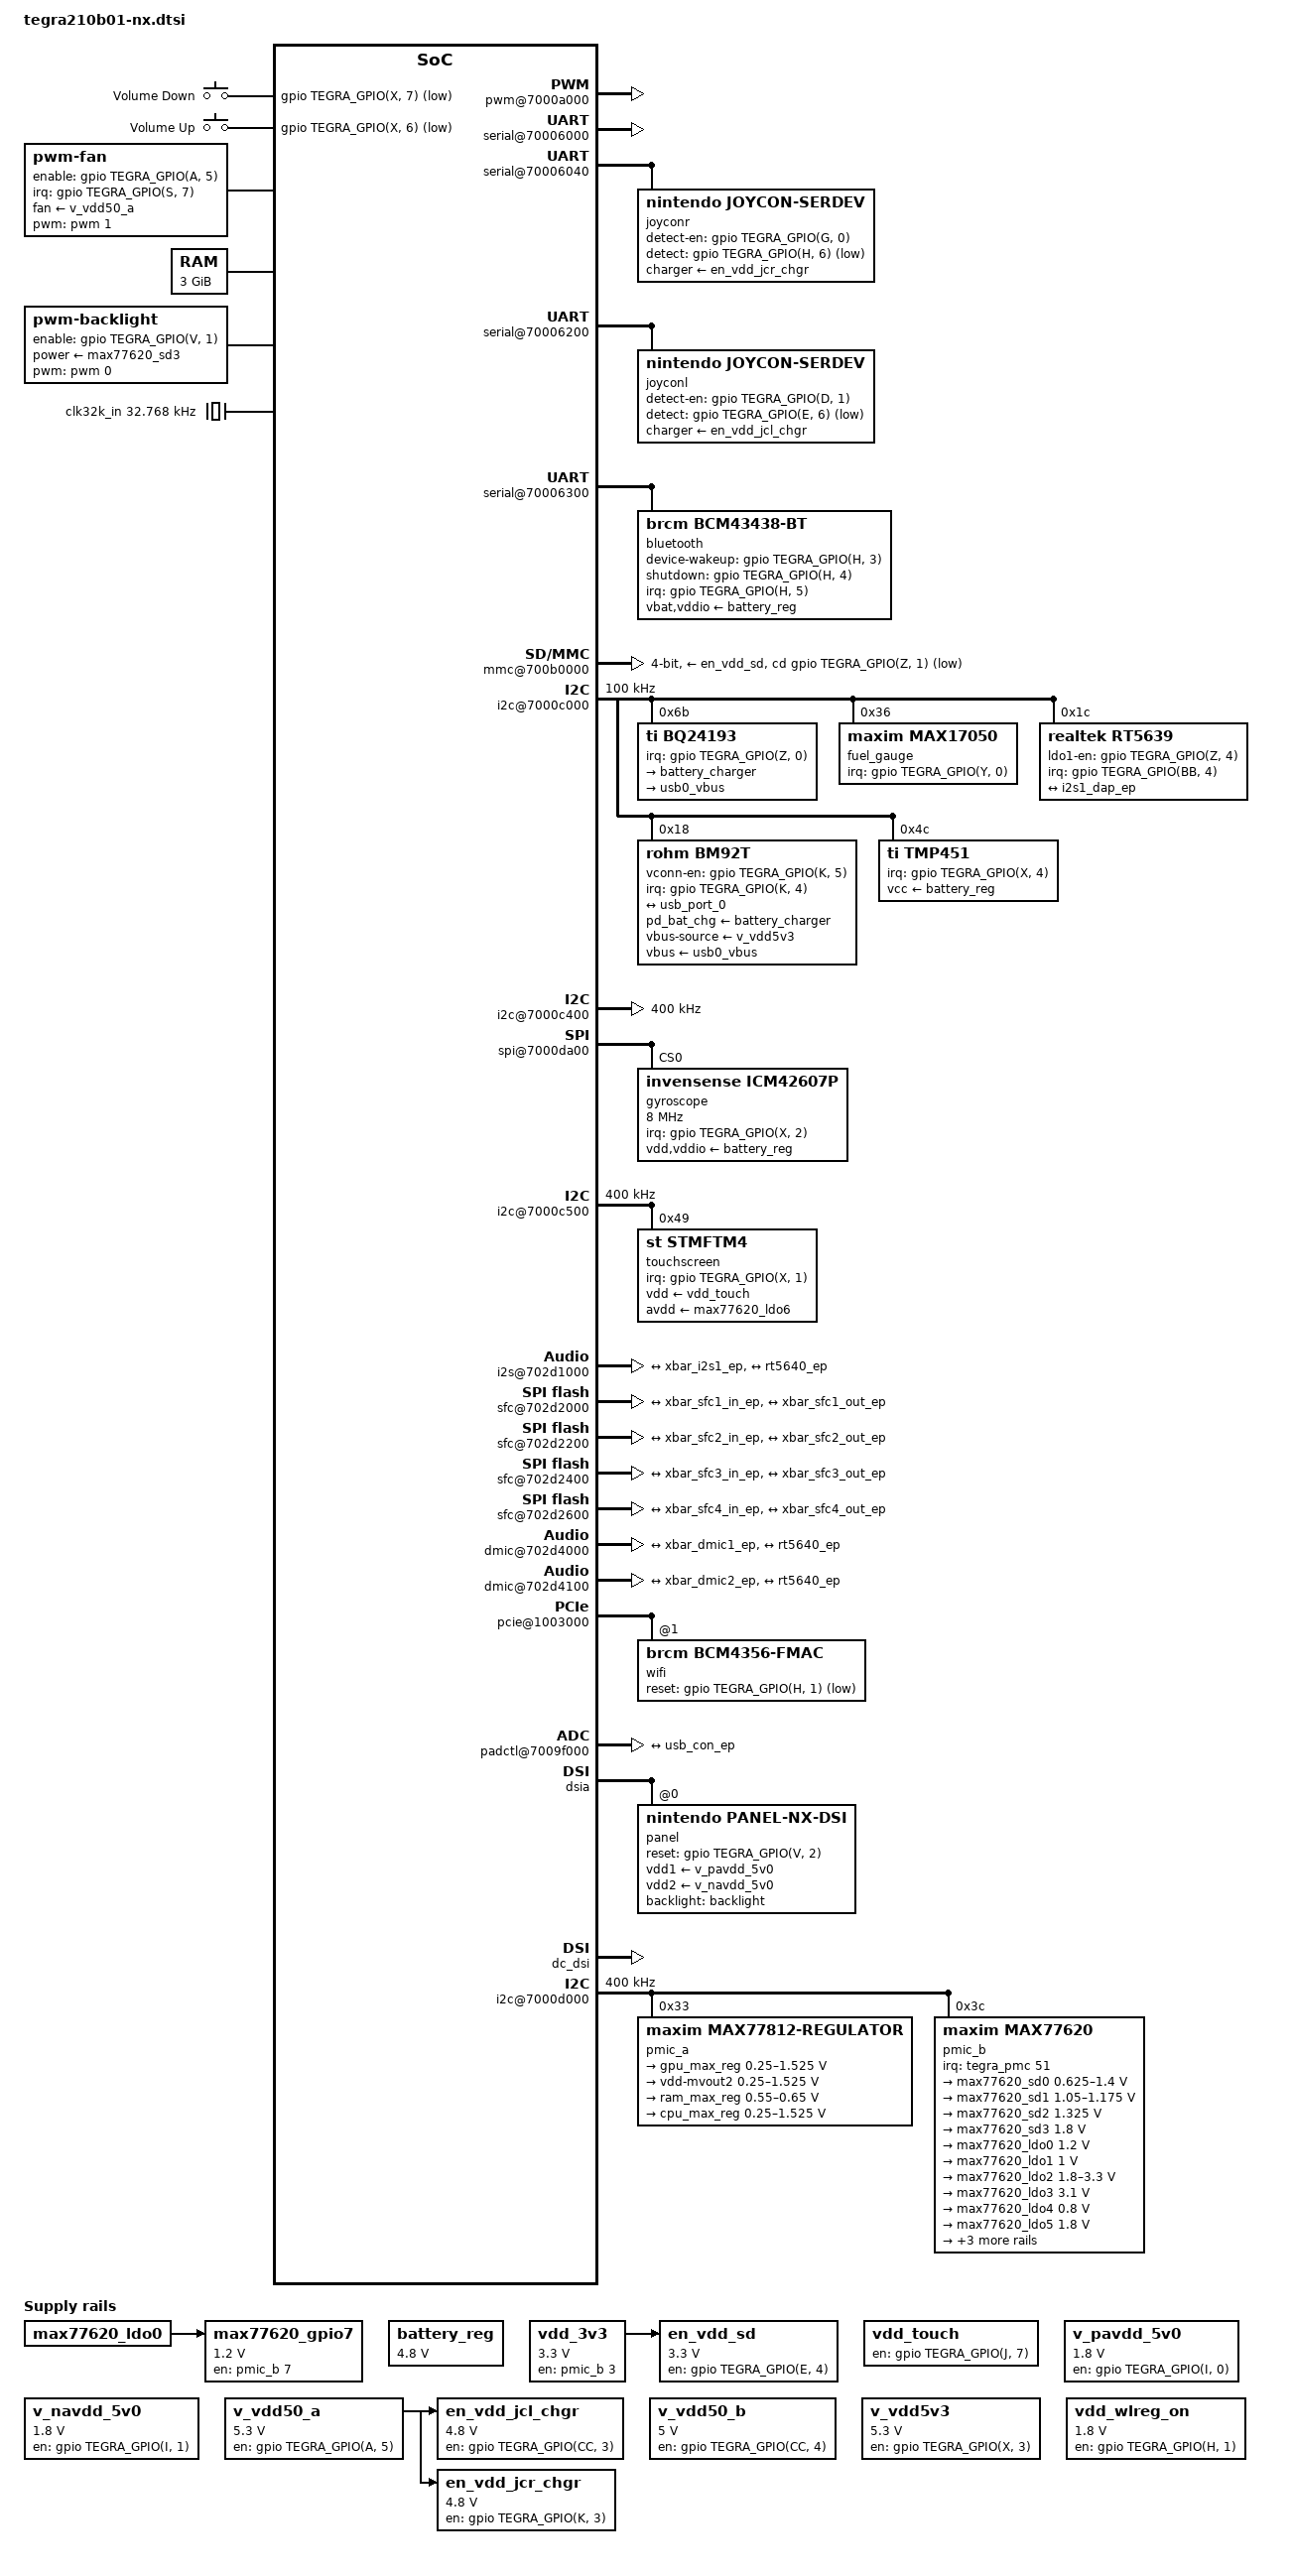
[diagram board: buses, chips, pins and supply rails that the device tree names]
// SPDX-License-Identifier: GPL-2.0
#include <dt-bindings/mfd/max77620.h>
#include <dt-bindings/thermal/thermal.h>
#include <dt-bindings/input/input.h>
#include <dt-bindings/pinctrl/pinctrl-tegra-io-pad.h>
#include <dt-bindings/soc/tegra-pmc.h>
#include <dt-bindings/sound/rt5640.h>

#include "tegra210b01.dtsi"

/ {
	aliases {
		serial0 = &uarta;
		serial1 = &uartb;
		serial2 = &uartc;
		serial3 = &uartd;
	};

	chosen {
		stdout-path = "serial0:115200n8";

		framebuffer {
			compatible = "simple-framebuffer";
			status = "disabled";
			memory-region = <&bootloader_fb>;
			width = <720>;
			height = <1280>;
			stride = <2880>;
			format = "a8b8g8r8";
			clocks = <&tegra_car TEGRA210_CLK_DISP1>,
				 <&tegra_car TEGRA210_CLK_DSIA>,
				 <&tegra_car TEGRA210_CLK_DSIALP>,
				 <&tegra_car TEGRA210_CLK_PLL_D_OUT0>,
				 <&tegra_car TEGRA210_CLK_PWM>;
			power-domains = <&pd_sor>;
		};
	};

	reserved-memory {
		#address-cells = <2>;
		#size-cells = <2>;
		ranges;

		bootloader_fb: framebuffer@f5a00000 {
			reg = <0x0 0xf5a00000 0x0 0x400000>;
			iommu-addresses = <&dc_dsi 0x0 0xf5a00000 0x0 0x400000>;
			no-map;
		};
	};

	gpio-keys {
		compatible = "gpio-keys";
		gpio-keys,name = "gpio-keys";

		power {
			label = "Power";
			gpios = <&gpio TEGRA_GPIO(X, 5) GPIO_ACTIVE_LOW>;
			linux,code = <KEY_POWER>;
			debounce-interval = <16>;
			gpio-key,wakeup;

			status = "disabled"; /* Only hooked on Vali. max77620 is preferred. */
		};

		volume_down {
			label = "Volume Down";
			gpios = <&gpio TEGRA_GPIO(X, 7) GPIO_ACTIVE_LOW>;
			linux,code = <KEY_VOLUMEDOWN>;
			debounce-interval = <16>;
		};

		volume_up {
			label = "Volume Up";
			gpios = <&gpio TEGRA_GPIO(X, 6) GPIO_ACTIVE_LOW>;
			linux,code = <KEY_VOLUMEUP>;
			debounce-interval = <16>;
		};
	};

	firmware {
		android {
			compatible = "android,firmware";
			boot_devices = "700b0000.mmc";
			hardware = "nx";
		};
	};

	fan: pwm-fan {
		compatible = "pwm-fan";
		cooling-min-state = <0>;
		cooling-max-state = <5>;
		#cooling-cells = <2>;
		pwms = <&pwm 1 33333>;
		fan-supply = <&v_vdd50_a>;
		enable-gpios = <&gpio TEGRA_GPIO(A, 5) GPIO_ACTIVE_HIGH>;
		/* cooling level (0, 1, 2, 3, 4, 5) - pwm inverted */
		cooling-levels = <255 204 153 102 51 1>;

		interrupt-parent = <&gpio>;
		interrupts = <TEGRA_GPIO(S, 7) IRQ_TYPE_EDGE_RISING>;
	};

	r2p {
		compatible = "nvidia,tegra210b01-r2p";
		nvidia,pmc = <&pmc>;
		status = "okay";
	};

	memory@80000000 {
		device_type = "memory";
		reg = <0x0 0x80000000 0x0 0xc0000000>;
	};

	pwm@7000a000 {
		status = "okay";
		#pwm-cells = <2>;
		pinctrl-names = "default", "sleep";
		pinctrl-0 = <&fan_pwm_default>;
		pinctrl-1 = <&fan_pwm_sleep>;
	};

	pinmux@700008d4 {
		fan_pwm_default: fan-pwm-default {
			lcd_gpio2_pv4 {
				nvidia,pins = "lcd_gpio2_pv4";
				nvidia,function = "pwm1";
				nvidia,pull = <TEGRA_PIN_PULL_NONE>;
				nvidia,tristate = <TEGRA_PIN_DISABLE>;
				nvidia,enable-input = <TEGRA_PIN_DISABLE>;
			};
		};

		fan_pwm_sleep: fan-pwm-sleep {
			lcd_gpio2_pv4 {
				nvidia,pins = "lcd_gpio2_pv4";
				nvidia,function = "pwm1";
				nvidia,pull = <TEGRA_PIN_PULL_UP>;
				nvidia,tristate = <TEGRA_PIN_ENABLE>;
				nvidia,enable-input = <TEGRA_PIN_DISABLE>;
			};
		};
	};

	serial@70006000 {
		/delete-property/ dmas;
		/delete-property/ dma-names;
		status = "okay";
	};

	serial@70006040 {
		status = "okay";
		compatible = "nvidia,tegra124-hsuart", "nvidia,tegra30-hsuart";
		nvidia,invert-txd;
		nvidia,invert-rts;
		reset-names = "serial";

		joyconr {
			status = "okay";
			compatible = "nintendo,joycon-serdev";
			charger-supply = <&en_vdd_jcr_chgr>;
			detect-en-gpios = <&gpio TEGRA_GPIO(G, 0) GPIO_ACTIVE_HIGH>;
			detect-gpios = <&gpio TEGRA_GPIO(H, 6) GPIO_ACTIVE_LOW>;
		};
	};

	serial@70006200 {
		status = "okay";
		compatible = "nvidia,tegra124-hsuart", "nvidia,tegra30-hsuart";
		nvidia,invert-txd;
		nvidia,invert-rts;
		reset-names = "serial";

		joyconl {
			status = "okay";
			compatible = "nintendo,joycon-serdev";
			charger-supply = <&en_vdd_jcl_chgr>;
			detect-en-gpios = <&gpio TEGRA_GPIO(D, 1) GPIO_ACTIVE_HIGH>;
			detect-gpios = <&gpio TEGRA_GPIO(E, 6) GPIO_ACTIVE_LOW>;
		};

		sio {
			status = "disabled";
			compatible = "nintendo,joycon-serdev";
			nintendo,sio;
			nintendo,sio-home-gpio = <&gpio TEGRA_GPIO(V, 3) GPIO_ACTIVE_LOW>;
			nintendo,sio-por-gpio = <&gpio TEGRA_GPIO(CC, 5) GPIO_ACTIVE_HIGH>;
			nintendo,sio-rst-gpio = <&gpio TEGRA_GPIO(T, 1) GPIO_ACTIVE_HIGH>;

			sio-stick-cnt-off-l = <0 0xFFFFFF00>;
			sio-stick-cnt-off-r = <0xFFFFFF00 0>;

			clocks = <&tegra_pmc TEGRA_PMC_CLK_OUT_2>;
			clock-names = "sio";
			assigned-clocks = <&tegra_car TEGRA210_CLK_EXTERN2>,
					  <&tegra_pmc TEGRA_PMC_CLK_OUT_2>;
			assigned-clock-parents = <&tegra_car TEGRA210_CLK_PLL_P>,
						 <&tegra_car TEGRA210_CLK_EXTERN2>;
			assigned-clock-rates = <4000000>, <0>;
		};
	};

	serial@70006300 {
		/delete-property/ reg-shift;
		status = "okay";
		compatible = "nvidia,tegra124-hsuart", "nvidia,tegra30-hsuart";
		reset-names = "serial";

		bluetooth {
		    status = "okay";
			compatible = "brcm,bcm43438-bt";
			vbat-supply = <&battery_reg>;
			vddio-supply = <&battery_reg>;
			device-wakeup-gpios = <&gpio TEGRA_GPIO(H, 3) GPIO_ACTIVE_HIGH>;
			shutdown-gpios = <&gpio TEGRA_GPIO(H, 4) GPIO_ACTIVE_HIGH>;
			interrupt-parent = <&gpio>;
			interrupts = <TEGRA_GPIO(H, 5) IRQ_TYPE_LEVEL_LOW>;
			interrupt-names = "host-wakeup";
			max-speed = <3000000>; /* Max supported 4 MBaud */
		};
	};

	/* SDMMC1 for SD Card */
	mmc@700b0000 {
		status = "okay";
		bus-width = <4>;
		assigned-clocks = <&tegra_car TEGRA210_CLK_SDMMC1>,
				  <&tegra_car TEGRA210_CLK_PLL_C4>;
		assigned-clock-parents = <&tegra_car TEGRA210_CLK_PLL_C4_OUT0>;
		assigned-clock-rates = <0>, <998400000>;

		cap-sd-highspeed;
		sd-uhs-sdr12;
		sd-uhs-sdr50;
		sd-uhs-sdr104;

		cd-gpios = <&gpio TEGRA_GPIO(Z, 1) GPIO_ACTIVE_LOW>;

		vmmc-supply = <&en_vdd_sd>;
		vqmmc-supply = <&max77620_ldo2>;
	};

	/* SDMMC2 for Gamecard */
	mmc@700b0200 {
		status = "disabled";
		bus-width = <8>;

		mmc-ddr-1_8v;
		mmc-hs400-1_8v;
		mmc-hs200-1_8v;
		cap-mmc-highspeed;
		cap-sd-highspeed;
		non-removable;

		vqmmc-supply = <&max77620_sd3>;
		vmmc-supply = <&vdd_3v3>;
	};

	/* SDMMC3 Not Used */
	mmc@700b0400 {
		status = "disabled";
	};

	/* SDMMC4 for EMMC */
	mmc@700b0600 {
		status = "disabled";
		bus-width = <8>;

		cap-mmc-highspeed;
		mmc-ddr-1_8v;
		mmc-hs200-1_8v;
		mmc-hs400-1_8v;
		non-removable;

		vqmmc-supply = <&max77620_sd3>;
		vmmc-supply = <&vdd_3v3>;
	};

	i2c@7000c000 {
		status = "okay";
		clock-frequency = <100000>;

		bq24193@6b {
			compatible = "ti,bq24193";
			reg = <0x6b>;

			interrupt-parent = <&gpio>;
			interrupts = <TEGRA_GPIO(Z, 0) IRQ_TYPE_LEVEL_LOW>;

			monitored-battery = <&fuel_gauge>;

			omit-battery-class;

			battery_charger: charger {
				regulator-name = "batt_regulator";
				regulator-max-microamp = <4500000>;
			};

			usb0_vbus: usb-otg-vbus {
				regulator-name = "vbus_regulator";
			};
		};

		fuel_gauge: fuel-gauge@36 {
			compatible = "maxim,max17050";
			status = "okay";
			reg = <0x36>;

			interrupt-parent = <&gpio>;
			interrupts = <TEGRA_GPIO(Y, 0) IRQ_TYPE_EDGE_FALLING>;

			/* Actual is 5000 but driver does not account for CGAIN */
			/* And does not take into account Rsense and CGAIN for capacity */
			maxim,rsns-microohm = <10000>;
			maxim,over-heat-temp = <600>;
			maxim,dead-volt = <3000>;
			maxim,over-volt = <4208>; /* Actual: 4258 mV */

			#thermal-sensor-cells = <0>;
		};

		rt5639: audio-codec@1c {
			status = "okay";
			compatible = "realtek,rt5639";
			reg = <0x1c>;
			interrupt-parent = <&gpio>;
			interrupts = <TEGRA_GPIO(BB, 4) IRQ_TYPE_EDGE_RISING>;
			clocks = <&tegra_pmc TEGRA_PMC_CLK_OUT_1>;
			clock-names = "mclk";
			assigned-clocks = <&tegra_pmc TEGRA_PMC_CLK_OUT_1>;
			assigned-clock-parents = <&tegra_car TEGRA210_CLK_EXTERN1>;
			realtek,ldo1-en-gpios = <&gpio TEGRA_GPIO(Z, 4) GPIO_ACTIVE_HIGH>;
			realtek,over-current-threshold-microamp = <600>;
			realtek,over-current-scale-factor = <2>;
			realtek,dmic1-data-pin = <RT5640_DMIC1_DATA_PIN_NONE>;
			realtek,dmic2-data-pin = <RT5640_DMIC2_DATA_PIN_NONE>;
			realtek,jack-detect-source = <RT5640_JD_SRC_JD1_IN4P>;

			sound-name-prefix = "x";

			port {
				rt5640_ep: endpoint {
					remote-endpoint = <&i2s1_dap_ep>;
					mclk-fs = <256>;
				};
			};
		};

		/* PD Chip */
		bm92t: bm92t@18 {
			compatible = "rohm,bm92t";
			reg = <0x18>;
			interrupt-parent = <&gpio>;
			interrupts = <TEGRA_GPIO(K, 4) IRQ_TYPE_LEVEL_LOW>;
			pd_bat_chg-supply = <&battery_charger>;
			vbus-source-supply = <&v_vdd5v3>;
			vbus-supply = <&usb0_vbus>;
			rohm,vconn-en-gpio = <&gpio TEGRA_GPIO(K, 5) GPIO_ACTIVE_HIGH>;

			rohm,dp-lanes = <2>;
			rohm,dp-signal-toggle-on-resume;

			/* Absolute max is 2.4A, constrained by BQ24193 ILIM */
			rohm,pd-5v-current-limit-ma = <2000>;
			rohm,pd-9v-current-limit-ma = <2000>;
			rohm,pd-12v-current-limit-ma = <1500>;
			rohm,pd-15v-current-limit-ma = <1200>;

			connector {
				compatible = "usb-c-connector";
				label = "USB-C";
				power-role = "dual";
				data-role = "dual";
				displayport = <&sor1>;

				ports {
					#address-cells = <1>;
					#size-cells = <0>;

					port@0 {
						reg = <0>;
						usb_con_ep: endpoint {
							remote-endpoint = <&usb_port_0>;
						};
					};
				};
			};
		};

		tmp451: temperature-sensor@4c {
			compatible = "ti,tmp451";
			status = "okay";
			reg = <0x4c>;

			interrupt-parent = <&gpio>;
			interrupts = <TEGRA_GPIO(X, 4) IRQ_TYPE_EDGE_FALLING>;
			vcc-supply = <&battery_reg>;

			#thermal-sensor-cells = <1>;
		};
   	};

	/* i2c2 @ 400000hz
	29: rohm ambient light sensor
	*/
	i2c@7000c400 {
		status = "okay";
		clock-frequency = <400000>;

		bh1730fvc: bh1730fvc@29 {
			status = "disabled";
			compatible = "rohm,bh1730fvc";
			reg = <0x29>;
			als-vid-supply = <&max77620_ldo6>;
			als-vdd-supply = <&vdd_3v3>;
			rohm,integration-cycle = <38>;
			rohm,lux-multiplier = <3600>;

			rohm,opt-win-coeff = < 500 5002 7502
					       754 2250 2000
					      1029 1999 1667
					      1373  884  583
					      1879  309  165>;

			rohm,gain-coeff = < 2500     0
					    1600  7800
					      10 50000
					       0  1000>;
		};
	};

	spi@7000da00 {
		status = "okay";
		num-cs = <1>;

		#address-cells = <1>;
		#size-cells = <0>;

		gyroscope: imu@0 {
			reg = <0>;
			status = "okay";
			compatible = "invensense,icm42607p", "invensense,icm40607",
				     "st,lsm6ds3h", "st,lsm6dse", "st,lsm6dso";

			spi-max-frequency = <8000000>;

			spi-cpha;
			spi-cpol;

			interrupt-parent = <&gpio>;
			interrupts = <TEGRA_GPIO(X, 2) IRQ_TYPE_LEVEL_HIGH>;

			vdd-supply = <&battery_reg>;
			vddio-supply = <&battery_reg>;

			st,drdy-int-pin = <2>;

			nvidia,rx-clk-tap-delay = <0x1f>;
			nvidia,tx-clk-tap-delay = <0x0>;

			mount-matrix =
				"0", "-1", "0",
				"1",  "0", "0",
				"0",  "0", "1";
		};
	};

	/* i2c3 @ 400000hz
	49: stm touchscreen controller
	*/
	i2c@7000c500 {
		status = "okay";
		clock-frequency = <400000>;

		touchscreen@49 {
			compatible = "st,stmftm4";
			reg = <0x49>;
			interrupt-parent = <&gpio>;
			interrupts = <TEGRA_GPIO(X, 1) IRQ_TYPE_LEVEL_LOW>;
			touchscreen-size-x = <1280>;
			touchscreen-size-y = <720>;
			touch-key-connected;
			vdd-supply = <&vdd_touch>;
			avdd-supply = <&max77620_ldo6>;
		};
	};

	aconnect@702c0000 {
		status = "okay";

		ahub@702d0800 {
			status = "okay";

			admaif@702d0000 {
				status = "okay";
			};

			/* I2S1: RT5639 */
			i2s@702d1000 {
				status = "okay";

				ports {
					#address-cells = <1>;
					#size-cells = <0>;

					port@0 {
						reg = <0>;

						i2s1_cif_ep: endpoint {
							remote-endpoint = <&xbar_i2s1_ep>;
						};
					};

					i2s1_port: port@1 {
						reg = <1>;

						i2s1_dap_ep: endpoint {
							dai-format = "i2s";
							remote-endpoint = <&rt5640_ep>;
						};
					};
				};
			};

			/* I2S2: BCM4356-BT PCM */
			// i2s@702d1100 {
			// 	status = "okay";

			// 	ports {
 			// 		#address-cells = <1>;
 			// 		#size-cells = <0>;

 			// 		port@0 {
 			// 			reg = <0>;

 			// 			i2s2_cif_ep: endpoint {
 			// 				remote-endpoint = <&xbar_i2s2_ep>;
 			// 			};
 			// 		};

 			// 		i2s2_port: port@1 {
 			// 			reg = <1>;

 			// 			/*i2s2_dap_ep: endpoint {
 			// 				dai-format = "dsp_a";
 			// 				remote-endpoint = <&spdif1_ep>;
 			// 			};*/
 			// 		};
 			// 	};
			// };

			sfc@702d2000 {
				status = "okay";

				ports {
					#address-cells = <1>;
					#size-cells = <0>;

					port@0 {
						reg = <0>;

						sfc1_cif_in_ep: endpoint {
							remote-endpoint = <&xbar_sfc1_in_ep>;
						};
					};

					sfc1_out_port: port@1 {
						reg = <1>;

						sfc1_cif_out_ep: endpoint {
							remote-endpoint = <&xbar_sfc1_out_ep>;
						};
					};
				};
			};

			sfc@702d2200 {
				status = "okay";

				ports {
					#address-cells = <1>;
					#size-cells = <0>;

					port@0 {
						reg = <0>;

						sfc2_cif_in_ep: endpoint {
							remote-endpoint = <&xbar_sfc2_in_ep>;
						};
					};

					sfc2_out_port: port@1 {
						reg = <1>;

						sfc2_cif_out_ep: endpoint {
							remote-endpoint = <&xbar_sfc2_out_ep>;
						};
					};
				};
			};

			sfc@702d2400 {
				status = "okay";

				ports {
					#address-cells = <1>;
					#size-cells = <0>;

					port@0 {
						reg = <0>;

						sfc3_cif_in_ep: endpoint {
							remote-endpoint = <&xbar_sfc3_in_ep>;
						};
					};

					sfc3_out_port: port@1 {
						reg = <1>;

						sfc3_cif_out_ep: endpoint {
							remote-endpoint = <&xbar_sfc3_out_ep>;
						};
					};
				};
			};

			sfc@702d2600 {
				status = "okay";

				ports {
					#address-cells = <1>;
					#size-cells = <0>;

					port@0 {
						reg = <0>;

						sfc4_cif_in_ep: endpoint {
							remote-endpoint = <&xbar_sfc4_in_ep>;
						};
					};

					sfc4_out_port: port@1 {
						reg = <1>;

						sfc4_cif_out_ep: endpoint {
							remote-endpoint = <&xbar_sfc4_out_ep>;
						};
					};
				};
			};

			amx@702d3000 {
				status = "okay";

				ports {
					#address-cells = <1>;
					#size-cells = <0>;

					port@0 {
						reg = <0>;

						amx1_in1_ep: endpoint {
							remote-endpoint = <&xbar_amx1_in1_ep>;
						};
					};

					port@1 {
						reg = <1>;

						amx1_in2_ep: endpoint {
							remote-endpoint = <&xbar_amx1_in2_ep>;
						};
					};

					port@2 {
						reg = <2>;

						amx1_in3_ep: endpoint {
							remote-endpoint = <&xbar_amx1_in3_ep>;
						};
					};

					port@3 {
						reg = <3>;

						amx1_in4_ep: endpoint {
							remote-endpoint = <&xbar_amx1_in4_ep>;
						};
					};

					amx1_out_port: port@4 {
						reg = <4>;

						amx1_out_ep: endpoint {
							remote-endpoint = <&xbar_amx1_out_ep>;
						};
					};
				};
			};

			amx@702d3100 {
				status = "okay";

				ports {
					#address-cells = <1>;
					#size-cells = <0>;

					port@0 {
						reg = <0>;

						amx2_in1_ep: endpoint {
							remote-endpoint = <&xbar_amx2_in1_ep>;
						};
					};

					port@1 {
						reg = <1>;

						amx2_in2_ep: endpoint {
							remote-endpoint = <&xbar_amx2_in2_ep>;
						};
					};

					amx2_in3_port: port@2 {
						reg = <2>;

						amx2_in3_ep: endpoint {
							remote-endpoint = <&xbar_amx2_in3_ep>;
						};
					};

					amx2_in4_port: port@3 {
						reg = <3>;

						amx2_in4_ep: endpoint {
							remote-endpoint = <&xbar_amx2_in4_ep>;
						};
					};

					amx2_out_port: port@4 {
						reg = <4>;

						amx2_out_ep: endpoint {
							remote-endpoint = <&xbar_amx2_out_ep>;
						};
					};
				};
			};

			adx@702d3800 {
				status = "okay";

				ports {
					#address-cells = <1>;
					#size-cells = <0>;

					port@0 {
						reg = <0>;

						adx1_in_ep: endpoint {
							remote-endpoint = <&xbar_adx1_in_ep>;
						};
					};

					adx1_out1_port: port@1 {
						reg = <1>;

						adx1_out1_ep: endpoint {
							remote-endpoint = <&xbar_adx1_out1_ep>;
						};
					};

					adx1_out2_port: port@2 {
						reg = <2>;

						adx1_out2_ep: endpoint {
							remote-endpoint = <&xbar_adx1_out2_ep>;
						};
					};

					adx1_out3_port: port@3 {
						reg = <3>;

						adx1_out3_ep: endpoint {
							remote-endpoint = <&xbar_adx1_out3_ep>;
						};
					};

					adx1_out4_port: port@4 {
						reg = <4>;

						adx1_out4_ep: endpoint {
							remote-endpoint = <&xbar_adx1_out4_ep>;
						};
					};
				};
			};

			adx@702d3900 {
				status = "okay";

				ports {
					#address-cells = <1>;
					#size-cells = <0>;

					port@0 {
						reg = <0>;

						adx2_in_ep: endpoint {
							remote-endpoint = <&xbar_adx2_in_ep>;
						};
					};

					adx2_out1_port: port@1 {
						reg = <1>;

						adx2_out1_ep: endpoint {
							remote-endpoint = <&xbar_adx2_out1_ep>;
						};
					};

					adx2_out2_port: port@2 {
						reg = <2>;

						adx2_out2_ep: endpoint {
							remote-endpoint = <&xbar_adx2_out2_ep>;
						};
					};

					adx2_out3_port: port@3 {
						reg = <3>;

						adx2_out3_ep: endpoint {
							remote-endpoint = <&xbar_adx2_out3_ep>;
						};
					};

					adx2_out4_port: port@4 {
						reg = <4>;

						adx2_out4_ep: endpoint {
							remote-endpoint = <&xbar_adx2_out4_ep>;
						};
					};
				};
			};

			dmic@702d4000 {
				status = "okay";

				ports {
					#address-cells = <1>;
					#size-cells = <0>;

					port@0 {
						reg = <0>;

						dmic1_cif_ep: endpoint {
							remote-endpoint = <&xbar_dmic1_ep>;
						};
					};

					dmic1_port: port@1 {
						reg = <1>;

						dmic1_dap_ep: endpoint {
							remote-endpoint = <&rt5640_ep>;
						};
					};
				};
			};

			dmic@702d4100 {
				status = "okay";

				ports {
					#address-cells = <1>;
					#size-cells = <0>;

					port@0 {
						reg = <0>;

						dmic2_cif_ep: endpoint {
							remote-endpoint = <&xbar_dmic2_ep>;
						};
					};

					dmic2_port: port@1 {
						reg = <1>;

						dmic2_dap_ep: endpoint {
							remote-endpoint = <&rt5640_ep>;
						};
					};
				};
			};

			processing-engine@702d8000 {
				status = "okay";

				ports {
					#address-cells = <1>;
					#size-cells = <0>;

					port@0 {
						reg = <0x0>;

						ope1_cif_in_ep: endpoint {
							remote-endpoint = <&xbar_ope1_in_ep>;
						};
					};

					ope1_out_port: port@1 {
						reg = <0x1>;

						ope1_cif_out_ep: endpoint {
							remote-endpoint = <&xbar_ope1_out_ep>;
						};
					};
				};
			};

			processing-engine@702d8400 {
				status = "okay";

				ports {
					#address-cells = <1>;
					#size-cells = <0>;

					port@0 {
						reg = <0x0>;

						ope2_cif_in_ep: endpoint {
							remote-endpoint = <&xbar_ope2_in_ep>;
						};
					};

					ope2_out_port: port@1 {
						reg = <0x1>;

						ope2_cif_out_ep: endpoint {
							remote-endpoint = <&xbar_ope2_out_ep>;
						};
					};
				};
			};

			mvc@702da000 {
				status = "okay";

				ports {
					#address-cells = <1>;
					#size-cells = <0>;

					port@0 {
						reg = <0>;

						mvc1_cif_in_ep: endpoint {
							remote-endpoint = <&xbar_mvc1_in_ep>;
						};
					};

					mvc1_out_port: port@1 {
						reg = <1>;

						mvc1_cif_out_ep: endpoint {
							remote-endpoint = <&xbar_mvc1_out_ep>;
						};
					};
				};
			};

			mvc@702da200 {
				status = "okay";

				ports {
					#address-cells = <1>;
					#size-cells = <0>;

					port@0 {
						reg = <0>;

						mvc2_cif_in_ep: endpoint {
							remote-endpoint = <&xbar_mvc2_in_ep>;
						};
					};

					mvc2_out_port: port@1 {
						reg = <1>;

						mvc2_cif_out_ep: endpoint {
							remote-endpoint = <&xbar_mvc2_out_ep>;
						};
					};
				};
			};

			amixer@702dbb00 {
				status = "okay";

				ports {
					#address-cells = <1>;
					#size-cells = <0>;

					port@0 {
						reg = <0x0>;

						mixer_in1_ep: endpoint {
							remote-endpoint = <&xbar_mixer_in1_ep>;
						};
					};

					port@1 {
						reg = <0x1>;

						mixer_in2_ep: endpoint {
							remote-endpoint = <&xbar_mixer_in2_ep>;
						};
					};

					port@2 {
						reg = <0x2>;

						mixer_in3_ep: endpoint {
							remote-endpoint = <&xbar_mixer_in3_ep>;
						};
					};

					port@3 {
						reg = <0x3>;

						mixer_in4_ep: endpoint {
							remote-endpoint = <&xbar_mixer_in4_ep>;
						};
					};

					port@4 {
						reg = <0x4>;

						mixer_in5_ep: endpoint {
							remote-endpoint = <&xbar_mixer_in5_ep>;
						};
					};

					port@5 {
						reg = <0x5>;

						mixer_in6_ep: endpoint {
							remote-endpoint = <&xbar_mixer_in6_ep>;
						};
					};

					port@6 {
						reg = <0x6>;

						mixer_in7_ep: endpoint {
							remote-endpoint = <&xbar_mixer_in7_ep>;
						};
					};

					port@7 {
						reg = <0x7>;

						mixer_in8_ep: endpoint {
							remote-endpoint = <&xbar_mixer_in8_ep>;
						};
					};

					port@8 {
						reg = <0x8>;

						mixer_in9_ep: endpoint {
							remote-endpoint = <&xbar_mixer_in9_ep>;
						};
					};

					port@9 {
						reg = <0x9>;

						mixer_in10_ep: endpoint {
							remote-endpoint = <&xbar_mixer_in10_ep>;
						};
					};

					mixer_out1_port: port@a {
						reg = <0xa>;

						mixer_out1_ep: endpoint {
							remote-endpoint = <&xbar_mixer_out1_ep>;
						};
					};

					mixer_out2_port: port@b {
						reg = <0xb>;

						mixer_out2_ep: endpoint {
							remote-endpoint = <&xbar_mixer_out2_ep>;
						};
					};

					mixer_out3_port: port@c {
						reg = <0xc>;

						mixer_out3_ep: endpoint {
							remote-endpoint = <&xbar_mixer_out3_ep>;
						};
					};

					mixer_out4_port: port@d {
						reg = <0xd>;

						mixer_out4_ep: endpoint {
							remote-endpoint = <&xbar_mixer_out4_ep>;
						};
					};

					mixer_out5_port: port@e {
						reg = <0xe>;

						mixer_out5_ep: endpoint {
							remote-endpoint = <&xbar_mixer_out5_ep>;
						};
					};
				};
			};

			ports {
				xbar_i2s1_port: port@a {
					reg = <0xa>;

					xbar_i2s1_ep: endpoint {
						remote-endpoint = <&i2s1_cif_ep>;
					};
				};

				// xbar_i2s2_port: port@b {
				// 	reg = <0xb>;

				// 	xbar_i2s2_ep: endpoint {
				// 		remote-endpoint = <&i2s2_cif_ep>;
				// 	};
				// };

				xbar_dmic1_port: port@f {
					reg = <0xf>;

					xbar_dmic1_ep: endpoint {
						remote-endpoint = <&dmic1_cif_ep>;
					};
				};

				xbar_dmic2_port: port@10 {
					reg = <0x10>;

					xbar_dmic2_ep: endpoint {
						remote-endpoint = <&dmic2_cif_ep>;
					};
				};

				xbar_sfc1_in_port: port@12 {
					reg = <0x12>;

					xbar_sfc1_in_ep: endpoint {
						remote-endpoint = <&sfc1_cif_in_ep>;
					};
				};

				port@13 {
					reg = <0x13>;

					xbar_sfc1_out_ep: endpoint {
						remote-endpoint = <&sfc1_cif_out_ep>;
					};
				};

				xbar_sfc2_in_port: port@14 {
					reg = <0x14>;

					xbar_sfc2_in_ep: endpoint {
						remote-endpoint = <&sfc2_cif_in_ep>;
					};
				};

				port@15 {
					reg = <0x15>;

					xbar_sfc2_out_ep: endpoint {
						remote-endpoint = <&sfc2_cif_out_ep>;
					};
				};

				xbar_sfc3_in_port: port@16 {
					reg = <0x16>;

					xbar_sfc3_in_ep: endpoint {
						remote-endpoint = <&sfc3_cif_in_ep>;
					};
				};

				port@17 {
					reg = <0x17>;

					xbar_sfc3_out_ep: endpoint {
						remote-endpoint = <&sfc3_cif_out_ep>;
					};
				};

				xbar_sfc4_in_port: port@18 {
					reg = <0x18>;

					xbar_sfc4_in_ep: endpoint {
						remote-endpoint = <&sfc4_cif_in_ep>;
					};
				};

				port@19 {
					reg = <0x19>;

					xbar_sfc4_out_ep: endpoint {
						remote-endpoint = <&sfc4_cif_out_ep>;
					};
				};

				xbar_mvc1_in_port: port@1a {
					reg = <0x1a>;

					xbar_mvc1_in_ep: endpoint {
						remote-endpoint = <&mvc1_cif_in_ep>;
					};
				};

				port@1b {
					reg = <0x1b>;

					xbar_mvc1_out_ep: endpoint {
						remote-endpoint = <&mvc1_cif_out_ep>;
					};
				};

				xbar_mvc2_in_port: port@1c {
					reg = <0x1c>;

					xbar_mvc2_in_ep: endpoint {
						remote-endpoint = <&mvc2_cif_in_ep>;
					};
				};

				port@1d {
					reg = <0x1d>;

					xbar_mvc2_out_ep: endpoint {
						remote-endpoint = <&mvc2_cif_out_ep>;
					};
				};

				xbar_amx1_in1_port: port@1e {
					reg = <0x1e>;

					xbar_amx1_in1_ep: endpoint {
						remote-endpoint = <&amx1_in1_ep>;
					};
				};

				xbar_amx1_in2_port: port@1f {
					reg = <0x1f>;

					xbar_amx1_in2_ep: endpoint {
						remote-endpoint = <&amx1_in2_ep>;
					};
				};

				xbar_amx1_in3_port: port@20 {
					reg = <0x20>;

					xbar_amx1_in3_ep: endpoint {
						remote-endpoint = <&amx1_in3_ep>;
					};
				};

				xbar_amx1_in4_port: port@21 {
					reg = <0x21>;

					xbar_amx1_in4_ep: endpoint {
						remote-endpoint = <&amx1_in4_ep>;
					};
				};

				port@22 {
					reg = <0x22>;

					xbar_amx1_out_ep: endpoint {
						remote-endpoint = <&amx1_out_ep>;
					};
				};

				xbar_amx2_in1_port: port@23 {
					reg = <0x23>;

					xbar_amx2_in1_ep: endpoint {
						remote-endpoint = <&amx2_in1_ep>;
					};
				};

				xbar_amx2_in2_port: port@24 {
					reg = <0x24>;

					xbar_amx2_in2_ep: endpoint {
						remote-endpoint = <&amx2_in2_ep>;
					};
				};

				xbar_amx2_in3_port: port@25 {
					reg = <0x25>;

					xbar_amx2_in3_ep: endpoint {
						remote-endpoint = <&amx2_in3_ep>;
					};
				};

				xbar_amx2_in4_port: port@26 {
					reg = <0x26>;

					xbar_amx2_in4_ep: endpoint {
						remote-endpoint = <&amx2_in4_ep>;
					};
				};

				port@27 {
					reg = <0x27>;

					xbar_amx2_out_ep: endpoint {
						remote-endpoint = <&amx2_out_ep>;
					};
				};

				xbar_adx1_in_port: port@28 {
					reg = <0x28>;

					xbar_adx1_in_ep: endpoint {
						remote-endpoint = <&adx1_in_ep>;
					};
				};

				port@29 {
					reg = <0x29>;

					xbar_adx1_out1_ep: endpoint {
						remote-endpoint = <&adx1_out1_ep>;
					};
				};

				port@2a {
					reg = <0x2a>;

					xbar_adx1_out2_ep: endpoint {
						remote-endpoint = <&adx1_out2_ep>;
					};
				};

				port@2b {
					reg = <0x2b>;

					xbar_adx1_out3_ep: endpoint {
						remote-endpoint = <&adx1_out3_ep>;
					};
				};

				port@2c {
					reg = <0x2c>;

					xbar_adx1_out4_ep: endpoint {
						remote-endpoint = <&adx1_out4_ep>;
					};
				};

				xbar_adx2_in_port: port@2d {
					reg = <0x2d>;

					xbar_adx2_in_ep: endpoint {
						remote-endpoint = <&adx2_in_ep>;
					};
				};

				port@2e {
					reg = <0x2e>;

					xbar_adx2_out1_ep: endpoint {
						remote-endpoint = <&adx2_out1_ep>;
					};
				};

				port@2f {
					reg = <0x2f>;

					xbar_adx2_out2_ep: endpoint {
						remote-endpoint = <&adx2_out2_ep>;
					};
				};

				port@30 {
					reg = <0x30>;

					xbar_adx2_out3_ep: endpoint {
						remote-endpoint = <&adx2_out3_ep>;
					};
				};

				port@31 {
					reg = <0x31>;

					xbar_adx2_out4_ep: endpoint {
						remote-endpoint = <&adx2_out4_ep>;
					};
				};

				xbar_mixer_in1_port: port@32 {
					reg = <0x32>;

					xbar_mixer_in1_ep: endpoint {
						remote-endpoint = <&mixer_in1_ep>;
					};
				};

				xbar_mixer_in2_port: port@33 {
					reg = <0x33>;

					xbar_mixer_in2_ep: endpoint {
						remote-endpoint = <&mixer_in2_ep>;
					};
				};

				xbar_mixer_in3_port: port@34 {
					reg = <0x34>;

					xbar_mixer_in3_ep: endpoint {
						remote-endpoint = <&mixer_in3_ep>;
					};
				};

				xbar_mixer_in4_port: port@35 {
					reg = <0x35>;

					xbar_mixer_in4_ep: endpoint {
						remote-endpoint = <&mixer_in4_ep>;
					};
				};

				xbar_mixer_in5_port: port@36 {
					reg = <0x36>;

					xbar_mixer_in5_ep: endpoint {
						remote-endpoint = <&mixer_in5_ep>;
					};
				};

				xbar_mixer_in6_port: port@37 {
					reg = <0x37>;

					xbar_mixer_in6_ep: endpoint {
						remote-endpoint = <&mixer_in6_ep>;
					};
				};

				xbar_mixer_in7_port: port@38 {
					reg = <0x38>;

					xbar_mixer_in7_ep: endpoint {
						remote-endpoint = <&mixer_in7_ep>;
					};
				};

				xbar_mixer_in8_port: port@39 {
					reg = <0x39>;

					xbar_mixer_in8_ep: endpoint {
						remote-endpoint = <&mixer_in8_ep>;
					};
				};

				xbar_mixer_in9_port: port@3a {
					reg = <0x3a>;

					xbar_mixer_in9_ep: endpoint {
						remote-endpoint = <&mixer_in9_ep>;
					};
				};

				xbar_mixer_in10_port: port@3b {
					reg = <0x3b>;

					xbar_mixer_in10_ep: endpoint {
						remote-endpoint = <&mixer_in10_ep>;
					};
				};

				port@3c {
					reg = <0x3c>;

					xbar_mixer_out1_ep: endpoint {
						remote-endpoint = <&mixer_out1_ep>;
					};
				};

				port@3d {
					reg = <0x3d>;

					xbar_mixer_out2_ep: endpoint {
						remote-endpoint = <&mixer_out2_ep>;
					};
				};

				port@3e {
					reg = <0x3e>;

					xbar_mixer_out3_ep: endpoint {
						remote-endpoint = <&mixer_out3_ep>;
					};
				};

				port@3f {
					reg = <0x3f>;

					xbar_mixer_out4_ep: endpoint {
						remote-endpoint = <&mixer_out4_ep>;
					};
				};

				port@40 {
					reg = <0x40>;

					xbar_mixer_out5_ep: endpoint {
						remote-endpoint = <&mixer_out5_ep>;
					};
				};

				xbar_ope1_in_port: port@41 {
					reg = <0x41>;

					xbar_ope1_in_ep: endpoint {
						remote-endpoint = <&ope1_cif_in_ep>;
					};
				};

				port@42 {
					reg = <0x42>;

					xbar_ope1_out_ep: endpoint {
						remote-endpoint = <&ope1_cif_out_ep>;
					};
				};

				xbar_ope2_in_port: port@43 {
					reg = <0x43>;

					xbar_ope2_in_ep: endpoint {
						remote-endpoint = <&ope2_cif_in_ep>;
					};
				};

				port@44 {
					reg = <0x44>;

					xbar_ope2_out_ep: endpoint {
						remote-endpoint = <&ope2_cif_out_ep>;
					};
				};
			};
		};

		dma-controller@702e2000 {
			status = "okay";
		};

		interrupt-controller@702f9000 {
			status = "okay";
		};
	};

	gpu@57000000 {
		status = "okay";
		vdd-supply = <&gpu_max_reg>;
	};

	backlight: backlight {
		status = "okay";
		compatible = "pwm-backlight";
		pwms = <&pwm 0 33898>;
		pwm-names = "backlight";
		brightness-levels = <
			0 1 2 3 4 5 6 7 8 9 10 11 12 13 14 15 16
			17 18 19 20 21 22 23 24 25 26 27 28 29 30
			31 32 33 34 35 36 37 38 39 40 41 42 43 44
			45 46 47 48 49 50 51 52 53 54 55 56 57 58
			59 60 61 62 63 64 65 66 67 68 69 70 71 72
			73 74 75 76 77 78 79 80 81 82 83 84 85 86
			87 88 89 90 91 92 93 94 95 96 97 98 99 100
		>;
		default-brightness-level = <50>;
		enable-gpios = <&gpio TEGRA_GPIO(V, 1) GPIO_ACTIVE_HIGH>;
		power-supply = <&max77620_sd3>;
	};

	/* Fixed regulators */
	battery_reg: regulator@0 {
	    status = "okay";
		compatible = "regulator-fixed";
		reg = <0>;
		regulator-name = "vdd-ac-bat";
		regulator-min-microvolt = <4800000>;
		regulator-max-microvolt = <4800000>;
		regulator-always-on;
	};

	vdd_3v3: regulator@1 {
		compatible = "regulator-fixed";
		reg = <1>;
		regulator-name = "vdd-3v3";
		regulator-min-microvolt = <3300000>;
		regulator-max-microvolt = <3300000>;
		regulator-always-on;
		gpio = <&pmic_b 3 0>;
		enable-active-high;
		regulator-enable-ramp-delay = <160>;
		regulator-disable-ramp-delay = <10000>;
	};

	max77620_gpio7: avdd-dsi-csi-1v2 {
		compatible = "regulator-fixed";
		regulator-name = "max77620-gpio7";
		regulator-min-microvolt = <1200000>;
		regulator-max-microvolt = <1200000>;
		regulator-boot-on; /* Must be set for seamless display */
		gpio = <&pmic_b 7 0>;
		enable-active-high;
		regulator-enable-ramp-delay = <240>;
		regulator-disable-ramp-delay = <11340>;
		vin-supply = <&max77620_ldo0>;
	};

	// lcd_bl_en: regulator@3 {
	// 	compatible = "regulator-fixed";
	// 	reg = <3>;
	// 	status = "okay"; /* Only enabled on Odin/Modin/Vali */
	// 	regulator-name = "lcd-bl-en";
	// 	regulator-min-microvolt = <1800000>;
	// 	regulator-max-microvolt = <1800000>;
	// 	gpio = <&gpio TEGRA_GPIO(V, 1) 0>;
	// 	regulator-boot-on; /* Must be set for seamless display */
	// 	enable-active-high;
	// };

	vdd_touch: regulator-touch-vdd {
		compatible = "regulator-fixed";
		regulator-name = "touch-vdd";
		gpio = <&gpio TEGRA_GPIO(J, 7) GPIO_ACTIVE_HIGH>;
		enable-active-high;
		startup-delay-us = <5000>; // from downstream driver
	};

	en_vdd_sd: regulator@4 {
		compatible = "regulator-fixed";
		reg = <4>;
		regulator-name = "en-vdd-sd";
		regulator-min-microvolt = <3300000>;
		regulator-max-microvolt = <3300000>;
		gpio = <&gpio TEGRA_GPIO(E, 4) 0>;
		enable-active-high;
		regulator-enable-ramp-delay = <472>;
		regulator-disable-ramp-delay = <4880>;
		vin-supply = <&vdd_3v3>;
	};

	/* LCD Power Enable +5V. Rohm BD8316GWL. */
	v_pavdd_5v0: v-pavdd-5v0 {
		compatible = "regulator-fixed";
		regulator-name = "v_pavdd_5v0";
		regulator-min-microvolt = <1800000>;
		regulator-max-microvolt = <1800000>;
		gpio = <&gpio TEGRA_GPIO(I, 0) 0>;
		enable-active-high;
		regulator-boot-on; /* Must be set for seamless display */
		regulator-enable-ramp-delay = <232>;
	};

	/* LCD Power Enable -5V. Rohm BD8316GWL. */
	v_navdd_5v0: regulator@8 {
		compatible = "regulator-fixed";
		reg = <8>;
		status = "okay"; /* Only enabled on Odin/Modin/Vali*/
		regulator-name = "v_navdd_5v0";
		regulator-min-microvolt = <1800000>;
		regulator-max-microvolt = <1800000>;
		gpio = <&gpio TEGRA_GPIO(I, 1) 0>;
		enable-active-high;
		regulator-boot-on; /* Must be set for seamless display */
		regulator-enable-ramp-delay = <232>;
	};

	/* Joycon/Fan power (battery). Maxim MAX8969EWL53+. */
	v_vdd50_a: regulator@9 {
		compatible = "regulator-fixed";
		reg = <9>;
		regulator-name = "v_vdd50_a";
		regulator-min-microvolt = <5300000>;
		regulator-max-microvolt = <5300000>;
		gpio = <&gpio TEGRA_GPIO(A, 5) 0>;
		enable-active-high;
	};

	/* Joycon/Fan power (usb). DC0 on Odin. Maxim MAX8969EWL53+ on Modin. */
	v_vdd50_b: regulator@0xa {
		compatible = "regulator-fixed";
		reg = <10>;
		status = "okay"; /* Only enabled on Odin/Modin */
		regulator-name = "v_vdd50_b";
		regulator-min-microvolt = <5000000>;
		regulator-max-microvolt = <5000000>;
		gpio = <&gpio TEGRA_GPIO(CC, 4) 0>;
		enable-active-high;
	};

	/* VBUS power */
	v_vdd5v3: regulator@0xb {
		compatible = "regulator-fixed";
		status = "okay"; /* Only enabled on Modin/Vali/Fric */
		regulator-name = "v_vdd5v3";
		regulator-min-microvolt = <5300000>;
		regulator-max-microvolt = <5300000>;
		gpio = <&gpio TEGRA_GPIO(X, 3) 0>;
		enable-active-high;
		regulator-enable-ramp-delay = <10000>;
	};

	vdd3v3_gc: regulator@0xc {
		compatible = "regulator-fixed";
		status = "disabled"; /* Only on Odin */
		reg = <12>;
		regulator-name = "vdd3v3_gc";
		regulator-min-microvolt = <3300000>;
		regulator-max-microvolt = <3300000>;
		gpio = <&gpio TEGRA_GPIO(E, 5) 0>;
		enable-active-high;
		regulator-enable-ramp-delay = <472>;
		regulator-disable-ramp-delay = <4880>;
		vin-supply = <&vdd_3v3>;
	};

	vdd_wlreg_on: regulator@0xd {
		compatible = "regulator-fixed";
		reg = <13>;
		regulator-name = "vdd-wlreg_on";
		regulator-min-microvolt = <1800000>;
		regulator-max-microvolt = <1800000>;
		gpio = <&gpio TEGRA_GPIO(H, 1) 0>;
		regulator-boot-on;
		regulator-always-on;
		enable-active-high;
	};

	/* TI TCR2EE48 4.8V */
	en_vdd_jcl_chgr: regulator@0xe {
		compatible = "regulator-fixed";
		reg = <14>;
		status = "okay";
		regulator-name = "left-jc-reg";
		regulator-min-microvolt = <4800000>;
		regulator-max-microvolt = <4800000>;
		gpio = <&gpio TEGRA_GPIO(CC, 3) GPIO_ACTIVE_HIGH>;
		enable-active-high;
		vin-supply = <&v_vdd50_a>;
	};

	/* TI TCR2EE48 4.8V */
	en_vdd_jcr_chgr: regulator@0xf {
		compatible = "regulator-fixed";
		reg = <15>;
		status = "okay";
		regulator-name = "right-jc-reg";
		regulator-min-microvolt = <4800000>;
		regulator-max-microvolt = <4800000>;
		gpio = <&gpio TEGRA_GPIO(K, 3) GPIO_ACTIVE_HIGH>;
		enable-active-high;
		vin-supply = <&v_vdd50_a>;
	};

	soctherm@700E2000 {
		throttle-cfgs {
			/* PG/ACOK/USB OC pin. CLK_32K_OUT. Used for LED PWM on Vali. */
			throttle_oc1: oc1 { // Sticky mode but not supported.
				nvidia,priority = <16>;
				nvidia,polarity-active-low = <1>;
				nvidia,count-threshold = <0>;
				nvidia,throttle-period = <2500000>;
				nvidia,alarm-filter = <0xFFFFFFFF>;
				nvidia,cpu-throt-percent = <75>;
				nvidia,gpu-throt-level = <TEGRA_SOCTHERM_THROT_LEVEL_MED>;
			};

			/* Battery OC pin. GPIO_PL1. Traced but missing resistor. */
			throttle_oc2: oc2 {
				nvidia,priority = <24>;
				nvidia,polarity-active-low = <1>;
				nvidia,count-threshold = <0>;
				nvidia,throttle-period = <100>;
				nvidia,alarm-filter = <0xFFFFFFFF>;
				nvidia,cpu-throt-percent = <75>;
				nvidia,gpu-throt-level = <TEGRA_SOCTHERM_THROT_LEVEL_MED>;
			};

			/* throttle_oc3: oc3: GPIO_PZ5. Floating. */
		};
	};

	sound {
		status = "okay";

		compatible = "nvidia,tegra210-audio-graph-card";

		dais = /* FE */
			<&admaif1_port>, <&admaif2_port>, <&admaif3_port>,
			<&admaif4_port>, <&admaif5_port>, <&admaif6_port>,
			<&admaif7_port>, <&admaif8_port>, <&admaif9_port>,
			<&admaif10_port>,
			/* Router */
			<&xbar_i2s1_port>, /*<&xbar_i2s2_port>,*/
			<&xbar_dmic1_port>, <&xbar_dmic2_port>,
			<&xbar_sfc1_in_port>, <&xbar_sfc2_in_port>,
			<&xbar_sfc3_in_port>, <&xbar_sfc4_in_port>,
			<&xbar_mvc1_in_port>, <&xbar_mvc2_in_port>,
			<&xbar_amx1_in1_port>, <&xbar_amx1_in2_port>,
			<&xbar_amx1_in3_port>, <&xbar_amx1_in4_port>,
			<&xbar_amx2_in1_port>, <&xbar_amx2_in2_port>,
			<&xbar_amx2_in3_port>, <&xbar_amx2_in4_port>,
			<&xbar_adx1_in_port>, <&xbar_adx2_in_port>,
			<&xbar_mixer_in1_port>, <&xbar_mixer_in2_port>,
			<&xbar_mixer_in3_port>, <&xbar_mixer_in4_port>,
			<&xbar_mixer_in5_port>, <&xbar_mixer_in6_port>,
			<&xbar_mixer_in7_port>, <&xbar_mixer_in8_port>,
			<&xbar_mixer_in9_port>, <&xbar_mixer_in10_port>,
			<&xbar_ope1_in_port>, <&xbar_ope2_in_port>,
			/* HW accelerators */
			<&sfc1_out_port>, <&sfc2_out_port>,
			<&sfc3_out_port>, <&sfc4_out_port>,
			<&mvc1_out_port>, <&mvc2_out_port>,
			<&amx1_out_port>, <&amx2_out_port>,
			<&adx1_out1_port>, <&adx1_out2_port>,
			<&adx1_out3_port>, <&adx1_out4_port>,
			<&adx2_out1_port>, <&adx2_out2_port>,
			<&adx2_out3_port>, <&adx2_out4_port>,
			<&mixer_out1_port>, <&mixer_out2_port>,
			<&mixer_out3_port>, <&mixer_out4_port>,
			<&mixer_out5_port>,
			<&ope1_out_port>, <&ope2_out_port>,
			/* I/O DAP Ports */
			<&i2s1_port>/*, <&i2s2_port>*/,
			<&dmic1_port>, <&dmic2_port>;

		label = "switch-ape-rt5640";

		widgets =
			"Microphone",   "x Mic Jack",
			"Headphone",    "x Headphone Jack",
			"Speaker",      "x Int Spk";

		routing = /* I2S1 <-> RT5640 */
			"x AIF1 Playback",    "I2S1 DAP-Playback",
			"I2S1 DAP-Capture",   "x AIF1 Capture",
			/* RT5640 codec controls */
			"x Headphone Jack",   "x HPOL",
			"x Headphone Jack",   "x HPOR",
			"x Int Spk",          "x SPORP",
			"x Int Spk",          "x SPORN",
			"x Int Spk",          "x SPOLP",
			"x Int Spk",          "x SPOLN",
			"x IN1P",             "x Mic Jack",
			"x IN1P",             "x Mic Jack";
	};

	cpus {
		cpu@0 {
			#cooling-cells = <2>;
		};
	};

	thermal-zones {

		cpu-thermal {
			polling-delay-passive = <250>;
			polling-delay = <500>;
			status = "okay";

			trips {
				cpu_trip_throttle: throttle {
					temperature = <85000>;
					hysteresis = <3000>;
					type = "passive";
				};

				cpu_trip_critical: critical {
					temperature = <96500>;
					hysteresis = <0>;
					type = "critical";
				};

				cpu_trip_hot: hot {
					temperature = <90000>;
					hysteresis = <2000>;
					type = "hot";
				};

				cpu_fan_trip0: fan-trip0 {
					temperature = <42000>;
					hysteresis = <3000>;
					type = "active";
				};

				cpu_fan_trip1: fan-trip1 {
					temperature = <50000>;
					hysteresis = <3000>;
					type = "active";
				};

				cpu_fan_trip2: fan-trip2 {
					temperature = <57000>;
					hysteresis = <3000>;
					type = "active";
				};

				cpu_fan_trip3: fan-trip3 {
					temperature = <64000>;
					hysteresis = <3000>;
					type = "active";
				};

				cpu_fan_trip4: fan-trip4 {
					temperature = <70000>;
					hysteresis = <3000>;
					type = "active";
				};
			};

			cooling-maps {
				map0 {
					cooling-device = <&fan 1 1>;
					trip = <&cpu_fan_trip0>;
				};

				map1 {
					cooling-device = <&fan 2 2>;
					trip = <&cpu_fan_trip1>;
				};

				map2 {
					cooling-device = <&fan 3 3>;
					trip = <&cpu_fan_trip2>;
				};

				map3 {
					cooling-device = <&fan 4 4>;
					trip = <&cpu_fan_trip3>;
				};

				map4 {
					cooling-device = <&fan 5 5>;
					trip = <&cpu_fan_trip4>;
				};

				map5 {
					cooling-device = <&{/cpus/cpu@0} THERMAL_NO_LIMIT THERMAL_NO_LIMIT>;
					trip = <&cpu_trip_throttle>;
				};
			};
		};

		gpu-thermal {
			polling-delay-passive = <250>;
			polling-delay = <500>;

			trips {
				gpu_fan_trip0: fan-trip0 {
					temperature = <42000>;
					hysteresis = <3000>;
					type = "active";
				};

				gpu_fan_trip1: fan-trip1 {
					temperature = <50000>;
					hysteresis = <3000>;
					type = "active";
				};

				gpu_fan_trip2: fan-trip2 {
					temperature = <57000>;
					hysteresis = <3000>;
					type = "active";
				};

				gpu_fan_trip3: fan-trip3 {
					temperature = <64000>;
					hysteresis = <3000>;
					type = "active";
				};

				gpu_fan_trip4: fan-trip4 {
					temperature = <70000>;
					hysteresis = <3000>;
					type = "active";
				};
			};

			cooling-maps {
				map1 {
					cooling-device = <&fan 1 1>;
					trip = <&gpu_fan_trip0>;
				};

				map2 {
					cooling-device = <&fan 2 2>;
					trip = <&gpu_fan_trip1>;
				};

				map3 {
					cooling-device = <&fan 3 3>;
					trip = <&gpu_fan_trip2>;
				};

				map4 {
					cooling-device = <&fan 4 4>;
					trip = <&gpu_fan_trip3>;
				};

				map5 {
					cooling-device = <&fan 5 5>;
					trip = <&gpu_fan_trip4>;
				};
			};
		};

		pmic-thermal {
			polling-delay = <0>;
			polling-delay-passive = <0>;

			thermal-sensors = <&pmic_b>;
			trips {
				die_temp_thresh: hot-die {
					temperature = <120000>;
					type = "active";
					hysteresis = <0>;
				};
			};

			cooling-maps {
				map0 {
					trip = <&die_temp_thresh>;
					cooling-device = <&dummy_cool_dev THERMAL_NO_LIMIT
								THERMAL_NO_LIMIT>;
					contribution = <100>;
					cdev-type = "emergency-balanced";
				};
			};
		};

		charger-thermal {
			status = "okay";
			polling-delay = <0>;
			polling-delay-passive = <0>;

			thermal-sensors = <&battery_charger>;
			trips {
				die_temp_thresh_chg: hot-die {
					temperature = <120000>;
					type = "active";
					hysteresis = <0>;
				};
			};

			cooling-maps {
				map0 {
					trip = <&die_temp_thresh_chg>;
					cooling-device = <&dummy_cool_dev THERMAL_NO_LIMIT
								THERMAL_NO_LIMIT>;
					contribution = <100>;
					cdev-type = "emergency-balanced";
				};
			};
		};
	};

	pcie@1003000 {
		status = "okay";

		hvddio-pex-supply = <&max77620_sd3>;
		dvddio-pex-supply = <&max77620_ldo1>;
		vddio-pex-ctl-supply = <&max77620_sd3>;

		pci@1,0 {
			// nvidia,num-lanes = <2>; use 4 from default
			phys =	<&{/padctl@7009f000/pads/pcie/lanes/pcie-3}>, /* Referred to plat config */
				<&{/padctl@7009f000/pads/pcie/lanes/pcie-2}>;
			phy-names = "pcie-0", "pcie-1";
			status = "disabled";
		};

		pci@2,0 {
			status = "okay";
			nvidia,num-lanes = <1>;
			phys = <&{/padctl@7009f000/pads/pcie/lanes/pcie-0}>;
			phy-names = "pcie-0";

			wifi@1 { /* PCIE-0 (Port 1) */
				status = "okay";
				compatible = "brcm,bcm4356-fmac";
				reg = <1>;
				reset-gpios = <&gpio TEGRA_GPIO(H, 1) GPIO_ACTIVE_LOW>;
			};
		};
	};

	padctl@7009f000 {
		status =  "okay";

		pads {
			usb2 {
				status = "okay";

				lanes {
					usb2-0 {
						nvidia,hs_curr_level_offset = <6>;
						nvidia,function = "xusb";
						status = "okay";
					};
				};
			};

			pcie {
				status = "okay";

				lanes {
					/* BCM4356A3-WiFi */
					pcie-0 {
						nvidia,function = "pcie-x1";
						status = "okay";
					};

					/* Unused ports */
					pcie-1 {
						nvidia,function = "usb3-ss";
						status = "okay";
					};

					pcie-2 {
						nvidia,function = "pcie-x4";
						status = "okay";
					};

					pcie-3 {
						nvidia,function = "pcie-x4";
						status = "okay";
					};

					pcie-4 {
						nvidia,function = "usb3-ss";
						status = "okay";
					};

					/* USB3 port */
					pcie-5 {
						nvidia,function = "usb3-ss";
						status = "okay";
					};
				};
			};
		};

		ports {
			usb2-0 {
				status = "okay";
				mode = "otg";

				usb-role-switch;
				vbus-supply = <&battery_reg>;

				port {
					usb_port_0: endpoint@0 {
						reg = <0>;
						remote-endpoint = <&usb_con_ep>;
					};
				};
			};

			usb3-0 {
				status = "okay";
				nvidia,usb2-companion = <0>;
			};
		};
	};

	pmc: pmc@7000e400 {
		nvidia,invert-interrupt;
		nvidia,suspend-mode = <0>;
		nvidia,cpu-pwr-good-time = <0>;
		nvidia,cpu-pwr-off-time = <0>;
		nvidia,core-pwr-good-time = <13100 7800>;
		nvidia,core-pwr-off-time = <44160>;
		nvidia,core-power-req-active-high;
		nvidia,sys-clock-req-active-high;
		pinctrl-names = "default";
		pinctrl-0 = <&pmc_audio_hv &pmc_spi_hv &pmc_gpio>;
		status = "okay";

		pmc_audio_hv: audio-hv {
			pins = "audio-hv";
			power-source = <TEGRA_IO_PAD_VOLTAGE_1V8>;
		};

		pmc_spi_hv: spi-hv {
			pins = "spi-hv";
			power-source = <TEGRA_IO_PAD_VOLTAGE_1V8>;
		};

		pmc_gpio: gpio {
			pins = "gpio";
			power-source = <TEGRA_IO_PAD_VOLTAGE_1V8>;
		};

		bootrom-commands {
			reset-commands {
				nvidia,command-retries-count = <2>;
				nvidia,delay-between-commands-us = <10>;
				nvidia,wait-before-start-bus-clear-us = <10>;
				#address-cells = <1>;
				#size-cells = <0>;

				commands@68 {
					nvidia,command-names = "r2p-setup";
					reg = <0x68>;
					nvidia,enable-8bit-register;
					nvidia,enable-8bit-data;
					nvidia,controller-type-i2c;
					nvidia,controller-id = <4>;
					nvidia,enable-controller-reset;
					nvidia,write-commands = <
							0x13 0x00 /* r2p enc 0 */
							0x1A 0x00 /* r2p enc 1 */
							0x11 0x00 /* r2p mgc 0 */
							0x18 0x00 /* r2p mgc 1 */
							0x04 0x01 /* Update RTC regs */
						>;
				};

				commands@3c {
					nvidia,command-names = "pmic-rails";
					reg = <0x3c>;
					nvidia,enable-8bit-register;
					nvidia,enable-8bit-data;
					nvidia,controller-type-i2c;
					nvidia,controller-id = <4>;
					nvidia,enable-controller-reset;
					nvidia,write-commands = <
							0x16 0x20 /* Set 1.0V and disable SD0 */
							0x42 0x99 /* Wake reasons: SFT_RST/ACOK/LID/EN0 */
							0x41 0x80 /* Reboot */
						>;
				};
			};
		};
	};

	clk32k_in: clock-32k {
		compatible = "fixed-clock";
		clock-frequency = <32768>;
		#clock-cells = <0>;
	};

	host1x@50000000 {
		vic@54340000 {
			status = "disabled";
		};
		nvjpg@54380000 {
			status = "disabled";
		};
		nvdec@54480000 {
			status = "disabled";
		};
		nvenc@544c0000 {
			status = "disabled";
		};

		dsia: dsi@54300000 {
			status = "okay";

			avdd-dsi-csi-supply = <&max77620_ldo0>;

			panel@0 {
				reg = <0>;
				status = "okay";

				rotation = <270>;

				compatible = "nintendo,panel-nx-dsi";
				reset-gpios = <&gpio TEGRA_GPIO(V, 2) GPIO_ACTIVE_HIGH>;
				backlight = <&backlight>;
				vdd1-supply = <&v_pavdd_5v0>;
				vdd2-supply = <&v_navdd_5v0>;
			};
		};

		dsi@54400000 {
			status = "disabled";
		};

		dc_dsi: dc@54200000 {
			status = "okay";
			memory-region = <&bootloader_fb>;

			// pinctrl-names = "pad_ab_default", "pad_ab_idle",
			// 	"pad_cd_default", "pad_cd_idle";
			// pinctrl-0 = <&dsi_ab_pad_default>;
			// pinctrl-1 = <&dsi_ab_pad_idle>;
			// pinctrl-2 = <&dsi_cd_pad_default>;
			// pinctrl-3 = <&dsi_cd_pad_idle>;

			nvidia,outputs = <&dsia>;
		};

		/* tegradc.1: DP */
		dc@54240000 {
			status = "okay";

			nvidia,outputs = <&sor1>;
		};

		dpaux1: dpaux@54040000 {
			status = "okay";
		};

		sor1: sor@54580000 {
			status = "okay";
			nvidia,dpaux = <&dpaux1>;

			avdd-io-hdmi-dp-supply = <&max77620_ldo8>;
			vdd-hdmi-dp-pll-supply = <&max77620_sd3>;
		};
	};

	tegra_clk_dfll: clock@70110000 {
		status = "okay";
		vdd-cpu-supply = <&cpu_max_reg>;
		nvidia,align-step-uv = <5000>;
		nvidia,sample-rate = <12500>;
		nvidia,droop-ctrl = <0x00000f00>;
		nvidia,force-mode = <1>;
		nvidia,cf = <6>;
		nvidia,ci = <0>;
		nvidia,cg = <2>;
		nvidia,i2c-fs-rate = <400000>;
		nvidia,pmic-undershoot-gb = <0>; /* Use pmic default min */
		/* nvidia,dfll-max-freq-khz = <1683000>; */
	};

	cpus {
		#address-cells = <1>;
		#size-cells = <0>;

		cpu@0 {
			vdd-cpu-supply = <&cpu_max_reg>;
		};

		idle-states {
			cpu-sleep {
				status = "okay";
			};
		};
	};

	psci {
		compatible = "arm,psci-1.0";
		method = "smc";
	};

	i2c@7000d000 {
		status = "okay";
		clock-frequency = <400000>;

		pmic_a: pmic@33 {
			compatible = "maxim,max77812-regulator";
			reg = <0x33>;
			maxim,soft-start-slew-rate = <5000>;
			maxim,shutdown-slew-rate = <5000>;
			maxim,ramp-up-slew-rate = <5000>;
			maxim,ramp-down-slew-rate = <5000>;
			status = "okay";

			/* interrupt-parent = <&gpio>; */
			/* interrupts = <TEGRA_GPIO(K, 6) IRQ_TYPE_NONE>; */

			regulators {
				gpu_max_reg: m1vout {
					regulator-name = "vdd-gpu";
					regulator-min-microvolt = <250000>;
					regulator-max-microvolt = <1525000>;
					/* regulator-max-microamp = <10000000>; */ /* 0x33 cfg */
					/* regulator-max-microamp = <15000000>; */ /* 0x31 cfg */
					regulator-init-microvolt = <800000>;
					regulator-ramp-delay = <5000>;
					regulator-enable-ramp-delay = <5000>;
					regulator-disable-ramp-delay = <5000>;
					maxim,peak-current-limit-ua = <7200000>;
				};

				m2vout {
					regulator-name = "vdd-mvout2";
					regulator-min-microvolt = <250000>;
					regulator-max-microvolt = <1525000>;
					regulator-ramp-delay = <5000>;
					regulator-enable-ramp-delay = <5000>;
					regulator-disable-ramp-delay = <5000>;
					maxim,peak-current-limit-ua = <7200000>;
				};

				ram_max_reg: m3vout {
					status = "okay";
					regulator-name = "vddio-ddr";
					regulator-min-microvolt = <550000>; /* Set min lpddr4x normally allowed */
					regulator-max-microvolt = <650000>; /* Set max lpddr4x normally allowed */
					/* regulator-max-microamp = <5000000>; */
					regulator-always-on;
					regulator-boot-on;
					/* regulator-init-microvolt = <600000>; */ /* Controlled by bootloader */
					regulator-ramp-delay = <5000>;
					regulator-enable-ramp-delay = <5000>;
					regulator-disable-ramp-delay = <5000>;
					maxim,peak-current-limit-ua = <7200000>;
				};

				cpu_max_reg: m4vout {
					regulator-name = "vdd-cpu";
					regulator-min-microvolt = <250000>;
					regulator-max-microvolt = <1525000>;
					/* regulator-max-microamp = <5000000>; */
					regulator-always-on;
					regulator-boot-on;
					regulator-init-microvolt = <1000000>;
					regulator-ramp-delay = <5000>;
					regulator-enable-ramp-delay = <5000>;
					regulator-disable-ramp-delay = <5000>;
					maxim,peak-current-limit-ua = <7200000>;
				};
			};
		};

		pmic_b: pmic@3c {
			compatible = "maxim,max77620";
			reg = <0x3c>;
			interrupt-parent = <&tegra_pmc>;
			interrupts = <51 IRQ_TYPE_LEVEL_LOW>;

			#interrupt-cells = <2>;
			interrupt-controller;

			gpio-controller;
			#gpio-cells = <2>;

			pinctrl-names = "default";
			pinctrl-0 = <&max77620_default>;

			fps {
				#address-cells = <1>;
				#size-cells = <0>;

				fps0 {
					reg = <0>;
					maxim,shutdown-fps-time-period-us = <5120>;
					maxim,fps-event-source = <MAX77620_FPS_EVENT_SRC_EN0>;
				};

				fps1 {
					reg = <1>;
					maxim,shutdown-fps-time-period-us = <5120>;
					maxim,fps-event-source = <MAX77620_FPS_EVENT_SRC_EN1>;
					maxim,device-state-on-disabled-event = <MAX77620_FPS_INACTIVE_STATE_SLEEP>;
				};

				fps2 {
					reg = <2>;
					maxim,shutdown-fps-time-period-us = <5120>;
					maxim,fps-event-source = <MAX77620_FPS_EVENT_SRC_EN0>;
				};
			};

			// hog-0 {
			// 	gpio-hog;
			// 	output-high;
			// 	gpios = <2 GPIO_ACTIVE_HIGH>,
			// 		<7 GPIO_ACTIVE_HIGH>;
			// };

			max77620_default: pinmux {
				gpio0 {
					pins = "gpio0";
					function = "gpio";
				};

				/* max77812 chip enable */
				gpio1 {
					pins = "gpio1";
					function = "fps-out";
					drive-open-drain = <1>;
					maxim,active-fps-source = <MAX77620_FPS_SRC_0>;
					maxim,active-fps-power-up-slot = <5>;
					maxim,active-fps-power-down-slot = <0>;
				};

				/* max77812 vio and force m3vout force */
				gpio2 {
					pins = "gpio2";
					function = "fps-out";
					drive-open-drain = <1>;
					maxim,active-fps-source = <MAX77620_FPS_SRC_0>;
					maxim,active-fps-power-up-slot = <6>;
					maxim,active-fps-power-down-slot = <0>;
				};

				/* vdd_3v3 */
				gpio3 {
					pins = "gpio3";
					function = "fps-out";
					drive-open-drain = <1>;
					maxim,active-fps-source = <MAX77620_FPS_SRC_0>;
					maxim,active-fps-power-up-slot = <3>;
					maxim,active-fps-power-down-slot = <0>;
				};

				gpio4 {
					pins = "gpio4";
					function = "32k-out1";
				};

				gpio5_6_7 {
					pins = "gpio5", "gpio6", "gpio7";
					function = "gpio";
					drive-open-drain = <1>;
				};
			};

			regulators {
				in-ldo0-1-supply = <&max77620_sd2>;
				in-ldo7-8-supply = <&max77620_sd2>;

				max77620_sd0: sd0 {
					regulator-name = "vdd-core";
					regulator-min-microvolt = <625000>;
					regulator-max-microvolt = <1400000>;
					regulator-boot-on;
					regulator-always-on;
					maxim,active-fps-source = <MAX77620_FPS_SRC_1>;
					maxim,active-fps-power-up-slot = <1>;
					maxim,active-fps-power-down-slot = <7>;
					// regulator-initial-mode = <REGULATOR_MODE_NORMAL>;
					regulator-enable-ramp-delay = <50>;
					regulator-disable-ramp-delay = <4080>;
					maxim,ramp-rate-setting = <27500>;
					regulator-ramp-delay = <27500>;
				};

				max77620_sd1: sd1 {
					regulator-name = "vdd-ddr";
					regulator-min-microvolt = <1050000>;
					regulator-max-microvolt = <1175000>;
					regulator-always-on;
					regulator-boot-on;
					/* regulator-init-microvolt = <1100000>; */ /* Controlled by bootloader */
					// regulator-initial-mode = <REGULATOR_MODE_NORMAL>;
					maxim,active-fps-source = <MAX77620_FPS_SRC_0>;
					maxim,active-fps-power-up-slot = <5>;
					maxim,active-fps-power-down-slot = <2>;
					regulator-enable-ramp-delay = <60>;
					regulator-disable-ramp-delay = <145800>;
					maxim,ramp-rate-setting = <27500>;
					regulator-ramp-delay = <27500>;
				};

				max77620_sd2: sd2 {
					regulator-name = "vdd-pre-reg";
					regulator-min-microvolt = <1325000>;
					regulator-max-microvolt = <1325000>;
					regulator-always-on;
					regulator-boot-on;
					maxim,active-fps-source = <MAX77620_FPS_SRC_NONE>;
					maxim,active-fps-power-up-slot = <0>;
					maxim,active-fps-power-down-slot = <0>;
					regulator-enable-ramp-delay = <40>;
					regulator-disable-ramp-delay = <20000>;
					maxim,ramp-rate-setting = <27500>;
					regulator-ramp-delay = <27500>;
				};

				max77620_sd3: sd3 {
					regulator-name = "vdd-1v8";
					regulator-min-microvolt = <1800000>;
					regulator-max-microvolt = <1800000>;
					regulator-always-on;
					regulator-boot-on;
					maxim,active-fps-source = <MAX77620_FPS_SRC_0>;
					maxim,active-fps-power-up-slot = <2>;
					maxim,active-fps-power-down-slot = <4>;
					// regulator-initial-mode = <REGULATOR_MODE_NORMAL>;
					regulator-enable-ramp-delay = <50>;
					regulator-disable-ramp-delay = <118000>;
					maxim,ramp-rate-setting = <27500>;
					regulator-ramp-delay = <27500>;
				};

				max77620_ldo0: ldo0 {
					regulator-name = "avdd-sys";
					regulator-min-microvolt = <1200000>;
					regulator-max-microvolt = <1200000>;
					regulator-boot-on; /* Must be set for seamless display */
					maxim,active-fps-source = <MAX77620_FPS_SRC_NONE>;
					maxim,active-fps-power-up-slot = <0>;
					maxim,active-fps-power-down-slot = <0>;
					regulator-enable-ramp-delay = <50>;
					regulator-disable-ramp-delay = <4000>;
					maxim,ramp-rate-setting = <50000>;
					regulator-ramp-delay = <50000>;
				};

				max77620_ldo1: ldo1 {
					regulator-name = "vdd-pex";
					regulator-min-microvolt = <1000000>;
					regulator-max-microvolt = <1000000>;
					maxim,active-fps-source = <MAX77620_FPS_SRC_NONE>;
					maxim,active-fps-power-up-slot = <0>;
					maxim,active-fps-power-down-slot = <0>;
					regulator-enable-ramp-delay = <50>;
					regulator-disable-ramp-delay = <7000>;
					maxim,ramp-rate-setting = <50000>;
					regulator-ramp-delay = <50000>;
				};

				max77620_ldo2: ldo2 {
					regulator-name = "vddio-sdmmc1";
					regulator-min-microvolt = <1800000>;
					regulator-max-microvolt = <3300000>;
					maxim,active-fps-source = <MAX77620_FPS_SRC_NONE>;
					maxim,active-fps-power-up-slot = <0>;
					maxim,active-fps-power-down-slot = <0>;
					regulator-enable-ramp-delay = <100>;
					regulator-disable-ramp-delay = <6000>;
					maxim,ramp-rate-setting = <50000>;
					regulator-ramp-delay = <50000>;
				};

				max77620_ldo3: ldo3 {
					regulator-name = "vdd-gc-3v1";
					regulator-min-microvolt = <3100000>;
					regulator-max-microvolt = <3100000>;
					maxim,active-fps-source = <MAX77620_FPS_SRC_NONE>;
					maxim,active-fps-power-up-slot = <0>;
					maxim,active-fps-power-down-slot = <0>;
					regulator-enable-ramp-delay = <100>;
					regulator-disable-ramp-delay = <3000>;
					maxim,ramp-rate-setting = <50000>;
					regulator-ramp-delay = <50000>;
				};

				max77620_ldo4: ldo4 {
					regulator-name = "vdd-rtc";
					regulator-min-microvolt = <800000>;
					regulator-max-microvolt = <800000>;
					regulator-always-on;
					regulator-boot-on;
					maxim,active-fps-power-up-slot = <0>;
					maxim,active-fps-power-down-slot = <7>;
					maxim,active-fps-source = <MAX77620_FPS_SRC_0>;
					regulator-enable-ramp-delay = <50>;
					regulator-disable-ramp-delay = <610>;
					maxim,ramp-rate-setting = <50000>;
					regulator-ramp-delay = <50000>;
				};

				/* GC Card Vddio */
				max77620_ldo5: ldo5 {
					regulator-name = "vdd-gc-1v8";
					regulator-min-microvolt = <1800000>;
					regulator-max-microvolt = <1800000>;
					maxim,active-fps-source = <MAX77620_FPS_SRC_NONE>;
					maxim,active-fps-power-up-slot = <0>;
					maxim,active-fps-power-down-slot = <0>;
					regulator-enable-ramp-delay = <70>;
					regulator-disable-ramp-delay = <3000>;
					maxim,ramp-rate-setting = <50000>;
					regulator-ramp-delay = <50000>;
				};

				/* Touch Panel, ALS. Powers LDO 1V8. */
				max77620_ldo6: ldo6 {
					regulator-name = "vdd-tp-2v9";
					regulator-min-microvolt = <2900000>;
					regulator-max-microvolt = <2900000>;
					regulator-boot-on; /* Decrease por time for Touch Panel. */
					maxim,active-fps-source = <MAX77620_FPS_SRC_NONE>;
					maxim,active-fps-power-up-slot = <0>;
					maxim,active-fps-power-down-slot = <0>;
					regulator-enable-ramp-delay = <100>;
					regulator-disable-ramp-delay = <3000>;
					maxim,ramp-rate-setting = <50000>;
					regulator-ramp-delay = <50000>;
				};

				/* Not used on T210B01 */
				max77620_ldo7: ldo7 {
					regulator-name = "vdd-gen-pll-edp";
					regulator-min-microvolt = <1000000>;
					regulator-max-microvolt = <1000000>; /* 3100000 */
					maxim,active-fps-source = <MAX77620_FPS_SRC_NONE>;
					maxim,active-fps-power-up-slot = <0>;
					maxim,active-fps-power-down-slot = <0>;
					regulator-enable-ramp-delay = <50>;
					regulator-disable-ramp-delay = <2768>;
					maxim,ramp-rate-setting = <50000>;
					regulator-ramp-delay = <50000>;
				};

				/* Odin/Modin/Fric: DP. */
				/* Vali: Powers LDO 2V8 for Sio VDD
				 * Powers LDO 1V8 for I2C1 VDDQ and ALC5639.
				 */
				max77620_ldo8: ldo8 {
					regulator-name = "vdd-hdmi-dp";
					regulator-min-microvolt = <1000000>;
					regulator-max-microvolt = <1000000>;
					maxim,active-fps-source = <MAX77620_FPS_SRC_NONE>;
					maxim,active-fps-power-up-slot = <0>;
					maxim,active-fps-power-down-slot = <0>;
					regulator-enable-ramp-delay = <50>;
					regulator-disable-ramp-delay = <4000>;
					maxim,ramp-rate-setting = <50000>;
					regulator-ramp-delay = <50000>;
				};
			};

			onoff {
				maxim,onoff-keycode = <KEY_POWER>;
			};
		};
	};

	dummy_cool_dev: dummy-cool-dev {
		compatible = "dummy-cooling-dev";
		#cooling-cells = <2>; /* min followed by max */
	};
};
/*
&spdif_dit1 {
	sound-name-prefix = "x";

	port {
		spdif1_ep: endpoint {
			remote-endpoint = <&i2s2_dap_ep>;
			mclk-fs = <256>;
		};
	};
};
*/
